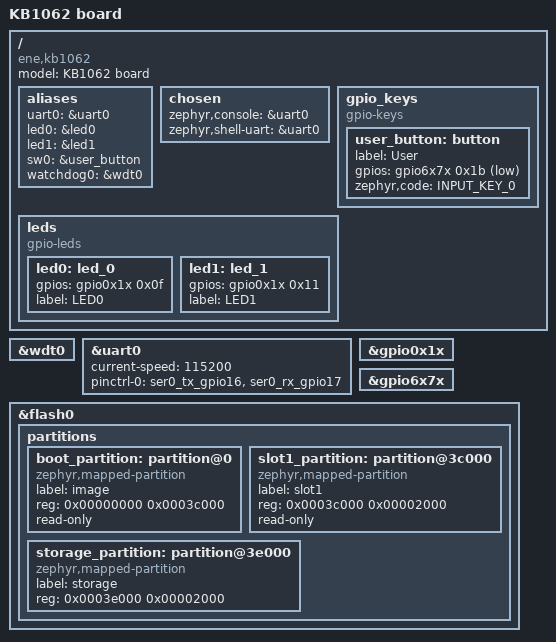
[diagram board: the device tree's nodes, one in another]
/*
 * Copyright (c) 2025-2026 ENE Technology Inc.
 *
 * SPDX-License-Identifier: Apache-2.0
 */

/dts-v1/;

#include <zephyr/dt-bindings/gpio/gpio.h>
#include <ene/kb106x/kb1062.dtsi>
#include <ene/kb106x/kb1062-pinctrl.dtsi>
#include <zephyr/dt-bindings/input/input-event-codes.h>
#include <common/mem.h>

/ {
	model = "KB1062 board";
	compatible = "ene,kb1062";

	aliases {
		uart0 = &uart0;
		led0 = &led0;
		led1 = &led1;
		sw0 = &user_button;
		watchdog0 = &wdt0;
	};

	chosen {
		zephyr,console = &uart0;
		zephyr,shell-uart = &uart0;
	};

	gpio_keys {
		compatible = "gpio-keys";

		user_button: button {
			label = "User";
			gpios = <&gpio6x7x 0x1b (GPIO_ACTIVE_LOW | GPIO_PULL_UP)>;
			zephyr,code = <INPUT_KEY_0>;
		};
	};

	leds {
		compatible = "gpio-leds";

		/* green led */
		led0: led_0 {
			gpios = <&gpio0x1x 0x0f GPIO_ACTIVE_HIGH>;
			label = "LED0";
		};

		/* blue led */
		led1: led_1 {
			gpios = <&gpio0x1x 0x11 GPIO_ACTIVE_HIGH>;
			label = "LED1";
		};
	};
};

&wdt0 {
	status = "okay";
};

&uart0 {
	status = "okay";
	current-speed = <115200>;
	pinctrl-0 = <&ser0_tx_gpio16 &ser0_rx_gpio17>;
	pinctrl-names = "default";
};

&gpio0x1x {
	status = "okay";
};

&gpio6x7x {
	status = "okay";
};

&flash0 {
	partitions {
		ranges;
		#address-cells = <1>;
		#size-cells = <1>;

		boot_partition: partition@0 {
			compatible = "zephyr,mapped-partition";
			label = "image";
			reg = <0x00000000 0x0003c000>;
			read-only;
		};

		slot1_partition: partition@3c000 {
			compatible = "zephyr,mapped-partition";
			label = "slot1";
			reg = <0x0003c000 0x00002000>;
			read-only;
		};

		storage_partition: partition@3e000 {
			compatible = "zephyr,mapped-partition";
			label = "storage";
			reg = <0x0003e000 0x00002000>;
		};
	};
};
